# CORE_NAME register map
Vendor: VENDOR_NAME
Registers are 32-bit, read-write, reset 0x0 unless marked. A register's access mark holds for its fields unless they carry their own. Offsets are from the block's base; lines under a group give offsets from that group; [hi:lo] are bit positions; {n}, {i} and the like mark numbered series; 'fields as' and 'values as' point back to an identical list; <NAME> marks a mode.

## Memory map
0xF0000000 GPIOA — General Purpose Input/output port A
0xF0010000 UART0 — Universal Async Receiver Transmiter
0xF0040000 DESS0 — Double Edge Syncronous Serial

## GPIOA — General Purpose Input/output port A
Base 0xF0000000
0x00 READ ro — Read input port
0x04 WRITE wo — Write output port
0x08 DIRECTION — Direction of port. 0 => input, 1 => output

## UART0 — Universal Async Receiver Transmiter
Base 0xF0010000
0x00 DATA — DATA port. write to add word to push to tx buffer, read to pop from rx buffer
  [7:0] DATA — Tx Fifo entry, Rx Fifo exit
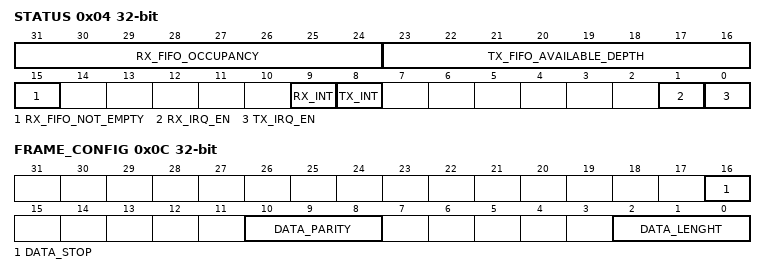
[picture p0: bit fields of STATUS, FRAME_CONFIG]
0x04 STATUS
  [31:24] RX_FIFO_OCCUPANCY ro — number of spots filled in the Rx FIFO
  [23:16] TX_FIFO_AVAILABLE_DEPTH ro — number of available spots in the TX fifo
  [15] RX_FIFO_NOT_EMPTY ro — 1 when rx fifo contains at least a word
  [9] RX_INT ro — RX Interrupt
  [8] TX_INT ro — TX Interrupt
  [1] RX_IRQ_EN — Rx Interrupt enable
  [0] TX_IRQ_EN — Tx interrupt enable
0x08 CLOCK_DIVIDER — clock divider for uart
  [19:0] CLOCK_DIVIDER — clock divider for UART
0x08 DIRECTION — Direction of port. 0 => input, 1 => output
0x0C FRAME_CONFIG — Uart frame configuration
  [16] DATA_STOP — uart stop bit
    0=ONE (one stop bit); 1=TWO (two stop bits)
  [10:8] DATA_PARITY
    0=NONE (No parity); 1=EVEN (Even parity); 2=ODD (Odd parity)
  [2:0] DATA_LENGHT — length of data - 1 (0x07 => 8 bit uart)

## DESS0 — Double Edge Syncronous Serial
Base 0xF0040000
0x00 DATA — data fifo(32) entry
  [15:0] DATA
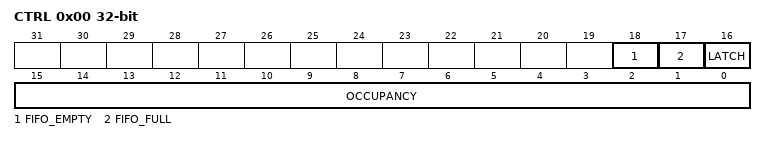
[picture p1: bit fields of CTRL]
0x00 CTRL — Control register for this peripheral
  [18] FIFO_EMPTY ro — indicates if the fifo is empty and the last word started transmitting
  [17] FIFO_FULL ro — indicates if Fifo is full. any word written to DATA while this bit is set will be droped
  [16] LATCH — read: device is latching, write: latch device
  [15:0] OCCUPANCY ro — level of the fifo buffer
